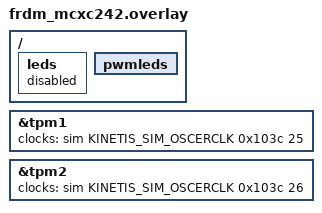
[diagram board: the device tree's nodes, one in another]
/*
 * Copyright 2024 NXP
 *
 * SPDX-License-Identifier: Apache-2.0
 */

/ {
	leds {
		status = "disabled";
	};

	pwmleds {
		status = "okay";
	};
};

&tpm1 {
	clocks = <&sim KINETIS_SIM_OSCERCLK 0x103c 25>;
};

&tpm2 {
	clocks = <&sim KINETIS_SIM_OSCERCLK 0x103c 26>;
};
